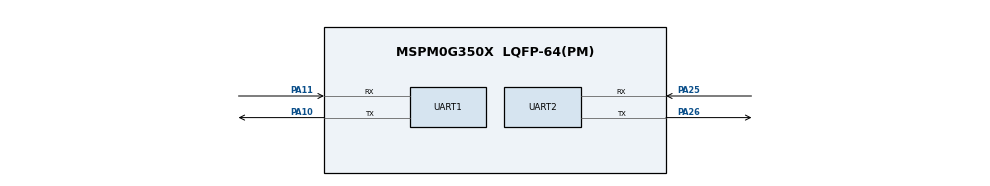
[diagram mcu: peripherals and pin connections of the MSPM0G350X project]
/**
 * @cliArgs --device "MSPM0G350X" --package "LQFP-64(PM)" --part "Default" --product "mspm0_sdk@2.01.00.03"
 * @versions {"tool":"1.20.0+3587"}
 */

/**
 * Import the modules used in this configuration.
 */
const GPIO          = scripting.addModule("/ti/driverlib/GPIO", {}, false);
const GPIO1         = GPIO.addInstance();
const GPIO2         = GPIO.addInstance();
const GPIO3         = GPIO.addInstance();
const GPIO4         = GPIO.addInstance();
const GPIO5         = GPIO.addInstance();
const GPIO6         = GPIO.addInstance();
const SYSCTL        = scripting.addModule("/ti/driverlib/SYSCTL");
const TIMER         = scripting.addModule("/ti/driverlib/TIMER", {}, false);
const TIMER1        = TIMER.addInstance();
const UART          = scripting.addModule("/ti/driverlib/UART", {}, false);
const UART1         = UART.addInstance();
const UART2         = UART.addInstance();
const ProjectConfig = scripting.addModule("/ti/project_config/ProjectConfig");

/**
 * Write custom configuration values to the imported modules.
 */
GPIO1.$name                          = "GPIO_SPI_OLED";
GPIO1.associatedPins.create(4);
GPIO1.associatedPins[0].assignedPort = "PORTA";
GPIO1.associatedPins[0].assignedPin  = "14";
GPIO1.associatedPins[0].$name        = "CLK";
GPIO1.associatedPins[1].assignedPort = "PORTA";
GPIO1.associatedPins[1].$name        = "SDA";
GPIO1.associatedPins[1].assignedPin  = "15";
GPIO1.associatedPins[2].$name        = "CS";
GPIO1.associatedPins[2].assignedPort = "PORTA";
GPIO1.associatedPins[2].assignedPin  = "16";
GPIO1.associatedPins[3].$name        = "DC";
GPIO1.associatedPins[3].assignedPort = "PORTA";
GPIO1.associatedPins[3].assignedPin  = "17";

const Board = scripting.addModule("/ti/driverlib/Board", {}, false);

GPIO2.$name                              = "GPIO_GRAY";
GPIO2.associatedPins.create(7);
GPIO2.associatedPins[0].direction        = "INPUT";
GPIO2.associatedPins[0].assignedPort     = "PORTA";
GPIO2.associatedPins[0].$name            = "PIN_1";
GPIO2.associatedPins[0].internalResistor = "PULL_DOWN";
GPIO2.associatedPins[0].interruptEn      = true;
GPIO2.associatedPins[0].polarity         = "RISE_FALL";
GPIO2.associatedPins[0].assignedPin      = "2";
GPIO2.associatedPins[1].$name            = "PIN_2";
GPIO2.associatedPins[1].assignedPort     = "PORTA";
GPIO2.associatedPins[1].internalResistor = "PULL_DOWN";
GPIO2.associatedPins[1].direction        = "INPUT";
GPIO2.associatedPins[1].interruptEn      = true;
GPIO2.associatedPins[1].polarity         = "RISE_FALL";
GPIO2.associatedPins[1].assignedPin      = "3";
GPIO2.associatedPins[2].$name            = "PIN_3";
GPIO2.associatedPins[2].assignedPort     = "PORTA";
GPIO2.associatedPins[2].internalResistor = "PULL_DOWN";
GPIO2.associatedPins[2].direction        = "INPUT";
GPIO2.associatedPins[2].interruptEn      = true;
GPIO2.associatedPins[2].polarity         = "RISE_FALL";
GPIO2.associatedPins[2].assignedPin      = "4";
GPIO2.associatedPins[3].$name            = "PIN_4";
GPIO2.associatedPins[3].assignedPort     = "PORTA";
GPIO2.associatedPins[3].internalResistor = "PULL_DOWN";
GPIO2.associatedPins[3].direction        = "INPUT";
GPIO2.associatedPins[3].interruptEn      = true;
GPIO2.associatedPins[3].polarity         = "RISE_FALL";
GPIO2.associatedPins[3].assignedPin      = "5";
GPIO2.associatedPins[4].$name            = "PIN_5";
GPIO2.associatedPins[4].assignedPort     = "PORTA";
GPIO2.associatedPins[4].internalResistor = "PULL_DOWN";
GPIO2.associatedPins[4].direction        = "INPUT";
GPIO2.associatedPins[4].interruptEn      = true;
GPIO2.associatedPins[4].polarity         = "RISE_FALL";
GPIO2.associatedPins[4].assignedPin      = "6";
GPIO2.associatedPins[5].$name            = "PIN_6";
GPIO2.associatedPins[5].assignedPort     = "PORTA";
GPIO2.associatedPins[5].assignedPin      = "7";
GPIO2.associatedPins[5].direction        = "INPUT";
GPIO2.associatedPins[5].interruptEn      = true;
GPIO2.associatedPins[5].polarity         = "RISE_FALL";
GPIO2.associatedPins[6].$name            = "PIN_7";
GPIO2.associatedPins[6].assignedPort     = "PORTA";
GPIO2.associatedPins[6].assignedPin      = "8";
GPIO2.associatedPins[6].direction        = "INPUT";
GPIO2.associatedPins[6].interruptEn      = true;
GPIO2.associatedPins[6].polarity         = "RISE_FALL";

GPIO3.$name                          = "GPIO_RESET";
GPIO3.associatedPins[0].direction    = "INPUT";
GPIO3.associatedPins[0].$name        = "BUTTON";
GPIO3.associatedPins[0].assignedPort = "PORTA";
GPIO3.associatedPins[0].assignedPin  = "1";
GPIO3.associatedPins[0].interruptEn  = true;
GPIO3.associatedPins[0].polarity     = "FALL";

GPIO4.$name                              = "GPIO_LED";
GPIO4.associatedPins[0].$name            = "PIN_0";
GPIO4.associatedPins[0].internalResistor = "PULL_UP";
GPIO4.associatedPins[0].assignedPort     = "PORTB";
GPIO4.associatedPins[0].assignedPin      = "9";

GPIO5.$name                              = "GPIO_STATE";
GPIO5.associatedPins.create(2);
GPIO5.associatedPins[0].$name            = "P0";
GPIO5.associatedPins[0].assignedPort     = "PORTA";
GPIO5.associatedPins[0].assignedPin      = "21";
GPIO5.associatedPins[0].direction        = "INPUT";
GPIO5.associatedPins[0].internalResistor = "PULL_DOWN";
GPIO5.associatedPins[1].$name            = "P1";
GPIO5.associatedPins[1].assignedPort     = "PORTA";
GPIO5.associatedPins[1].assignedPin      = "22";
GPIO5.associatedPins[1].direction        = "INPUT";
GPIO5.associatedPins[1].internalResistor = "PULL_DOWN";

GPIO6.$name                              = "GPIO_TASK";
GPIO6.associatedPins.create(4);
GPIO6.associatedPins[0].$name            = "BUTTON_1";
GPIO6.associatedPins[0].assignedPort     = "PORTA";
GPIO6.associatedPins[0].assignedPin      = "12";
GPIO6.associatedPins[0].direction        = "INPUT";
GPIO6.associatedPins[0].internalResistor = "PULL_DOWN";
GPIO6.associatedPins[0].interruptEn      = true;
GPIO6.associatedPins[0].polarity         = "RISE";
GPIO6.associatedPins[1].$name            = "BUTTON_2";
GPIO6.associatedPins[1].assignedPort     = "PORTA";
GPIO6.associatedPins[1].assignedPin      = "13";
GPIO6.associatedPins[1].direction        = "INPUT";
GPIO6.associatedPins[1].internalResistor = "PULL_DOWN";
GPIO6.associatedPins[1].interruptEn      = true;
GPIO6.associatedPins[1].polarity         = "RISE";
GPIO6.associatedPins[2].$name            = "BUTTON_3";
GPIO6.associatedPins[2].assignedPort     = "PORTA";
GPIO6.associatedPins[2].assignedPin      = "23";
GPIO6.associatedPins[2].direction        = "INPUT";
GPIO6.associatedPins[2].internalResistor = "PULL_DOWN";
GPIO6.associatedPins[2].interruptEn      = true;
GPIO6.associatedPins[2].polarity         = "RISE";
GPIO6.associatedPins[3].$name            = "BUTTON_4";
GPIO6.associatedPins[3].assignedPort     = "PORTA";
GPIO6.associatedPins[3].assignedPin      = "24";
GPIO6.associatedPins[3].direction        = "INPUT";
GPIO6.associatedPins[3].internalResistor = "PULL_DOWN";
GPIO6.associatedPins[3].interruptEn      = true;
GPIO6.associatedPins[3].polarity         = "RISE";

SYSCTL.forceDefaultClkConfig = true;

TIMER1.$name            = "TIMER_300ms";
TIMER1.timerPeriod      = "300 ms";
TIMER1.timerClkDiv      = 8;
TIMER1.timerClkPrescale = 200;
TIMER1.interrupts       = ["ZERO"];

UART1.$name                    = "UART_0";
UART1.targetBaudRate           = 115200;
UART1.enabledInterrupts        = ["RX"];
UART1.peripheral.rxPin.$assign = "PA11";
UART1.peripheral.txPin.$assign = "PA10";
UART1.txPinConfig.$name        = "ti_driverlib_gpio_GPIOPinGeneric0";
UART1.rxPinConfig.$name        = "ti_driverlib_gpio_GPIOPinGeneric1";

UART2.targetBaudRate                   = 115200;
UART2.$name                            = "UART_Send";
UART2.peripheral.rxPin.$assign         = "PA25";
UART2.peripheral.txPin.$assign         = "PA26";
UART2.txPinConfig.$name                = "ti_driverlib_gpio_GPIOPinGeneric2";
UART2.txPinConfig.direction            = scripting.forceWrite("OUTPUT");
UART2.txPinConfig.hideOutputInversion  = scripting.forceWrite(false);
UART2.txPinConfig.onlyInternalResistor = scripting.forceWrite(false);
UART2.txPinConfig.passedPeripheralType = scripting.forceWrite("Digital");
UART2.rxPinConfig.$name                = "ti_driverlib_gpio_GPIOPinGeneric3";
UART2.rxPinConfig.hideOutputInversion  = scripting.forceWrite(false);
UART2.rxPinConfig.onlyInternalResistor = scripting.forceWrite(false);
UART2.rxPinConfig.passedPeripheralType = scripting.forceWrite("Digital");

/**
 * Pinmux solution for unlocked pins/peripherals. This ensures that minor changes to the automatic solver in a future
 * version of the tool will not impact the pinmux you originally saw.  These lines can be completely deleted in order to
 * re-solve from scratch.
 */
GPIO1.associatedPins[0].pin.$suggestSolution = "PA14";
GPIO1.associatedPins[1].pin.$suggestSolution = "PA15";
GPIO1.associatedPins[2].pin.$suggestSolution = "PA16";
GPIO1.associatedPins[3].pin.$suggestSolution = "PA17";
Board.peripheral.$suggestSolution            = "DEBUGSS";
Board.peripheral.swclkPin.$suggestSolution   = "PA20";
Board.peripheral.swdioPin.$suggestSolution   = "PA19";
GPIO2.associatedPins[0].pin.$suggestSolution = "PA2";
GPIO2.associatedPins[1].pin.$suggestSolution = "PA3";
GPIO2.associatedPins[2].pin.$suggestSolution = "PA4";
GPIO2.associatedPins[3].pin.$suggestSolution = "PA5";
GPIO2.associatedPins[4].pin.$suggestSolution = "PA6";
GPIO2.associatedPins[5].pin.$suggestSolution = "PA7";
GPIO2.associatedPins[6].pin.$suggestSolution = "PA8";
GPIO3.associatedPins[0].pin.$suggestSolution = "PA1";
GPIO4.associatedPins[0].pin.$suggestSolution = "PB9";
GPIO5.associatedPins[0].pin.$suggestSolution = "PA21";
GPIO5.associatedPins[1].pin.$suggestSolution = "PA22";
GPIO6.associatedPins[0].pin.$suggestSolution = "PA12";
GPIO6.associatedPins[1].pin.$suggestSolution = "PA13";
GPIO6.associatedPins[2].pin.$suggestSolution = "PA23";
GPIO6.associatedPins[3].pin.$suggestSolution = "PA24";
SYSCTL.peripheral.$suggestSolution           = "SYSCTL";
TIMER1.peripheral.$suggestSolution           = "TIMA0";
UART1.peripheral.$suggestSolution            = "UART0";
UART2.peripheral.$suggestSolution            = "UART3";
